# ATtiny1626 register map
Vendor: Atmel; File version: 1.0
CPU: other r0p0, little endian, no MPU, no FPU, 4 interrupt priority bits
Registers are 8-bit, read-write, reset 0x0 unless marked. A register's access mark holds for its fields unless they carry their own. Offsets are from the block's base; [hi:lo] are bit positions; {n}, {i} and the like mark numbered series.

## CLKCTRL — Clock controller
Base 0x00800060
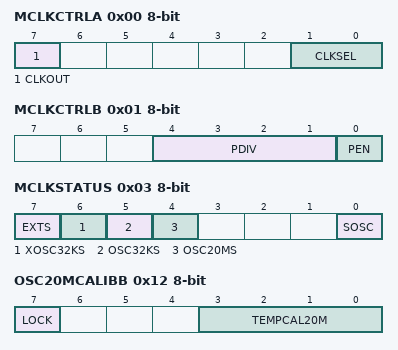
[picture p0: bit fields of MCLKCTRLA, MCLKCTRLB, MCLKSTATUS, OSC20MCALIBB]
0x00 MCLKCTRLA — MCLK Control A
  [7] CLKOUT — System clock out
  [1:0] CLKSEL — Clock
    0=OSC20M (20MHz oscillator); 1=OSCULP32K (32KHz oscillator); 2=XOSC32K (32.768kHz crystal oscillator); 3=EXTCLK (External clock)
0x01 MCLKCTRLB — MCLK Control B
  [4:1] PDIV — Prescaler division
    0=2X; 1=4X; 2=8X; 3=16X; 4=32X; 5=64X; 8=6X; 9=10X; 10=12X; 11=24X; 12=48X
  [0] PEN — Prescaler enable
0x02 MCLKLOCK
  [0] LOCKEN — lock ebable
0x03 MCLKSTATUS ro
  [7] EXTS — External Clock status
  [6] XOSC32KS — 32.768 kHz Crystal Oscillator status
  [5] OSC32KS — 32KHz oscillator status
  [4] OSC20MS — 20MHz oscillator status
  [0] SOSC — System Oscillator changing
0x10 OSC20MCTRLA — OSC20M Control A
  [1] RUNSTDBY — Run standby
0x11 OSC20MCALIBA — OSC20M Calibration A
  [6:0] CAL20M — Calibration
0x12 OSC20MCALIBB — OSC20M Calibration B
  [7] LOCK
  [3:0] TEMPCAL20M — Oscillator temperature coefficient
0x18 OSC32KCTRLA — OSC32K Control A
  [1] RUNSTDBY — Run standby
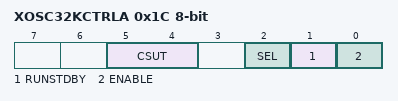
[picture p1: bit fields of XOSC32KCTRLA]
0x1C XOSC32KCTRLA — XOSC32K Control A
  [5:4] CSUT — Crystal startup time
    0=1K (1k cycles); 1=16K (16k cycles); 2=32K (32k cycles); 3=64K (64k cycles)
  [2] SEL — Select
  [1] RUNSTDBY — Run standby
  [0] ENABLE

## CPU
Base 0x00800034
0x00 CCP — Configuration Change Protection
  [7:0] CCP — CCP signature
    157=SPM (SPM Instruction Protection); 216=IOREG (IO Register Protection)
0x09 SP 16-bit (reset mask 0xFF) — Stack Pointer
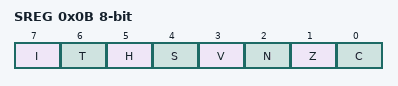
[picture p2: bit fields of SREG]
0x0B SREG — Status Register
  [7] I — Global Interrupt Enable Flag
  [6] T — Transfer Bit
  [5] H — Half Carry Flag
  [4] S — N Exclusive Or V Flag
  [3] V — Two's Complement Overflow Flag
  [2] N — Negative Flag
  [1] Z — Zero Flag
  [0] C — Carry Flag

## CPUINT — Interrupt Controller
Base 0x00800110
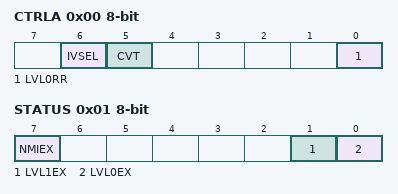
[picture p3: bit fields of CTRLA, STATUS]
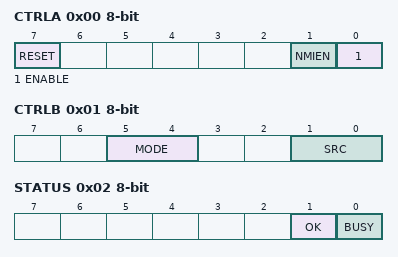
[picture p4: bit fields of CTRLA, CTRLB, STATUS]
0x00 CTRLA — Control A
  [6] IVSEL — Interrupt Vector Select
  [5] CVT — Compact Vector Table
  [0] LVL0RR — Round-robin Scheduling Enable
0x01 STATUS
  [7] NMIEX ro — Non-maskable Interrupt Executing
  [1] LVL1EX ro — Level 1 Interrupt Executing
  [0] LVL0EX ro — Level 0 Interrupt Executing
0x02 LVL0PRI — Interrupt Level 0 Priority
  [7:0] LVL0PRI — Interrupt Level Priority
0x03 LVL1VEC — Interrupt Level 1 Priority Vector
  [7:0] LVL1VEC — Interrupt Vector with High Priority

## CRCSCAN
Base 0x00800120
0x00 CTRLA — Control A
  [7] RESET — Reset CRC scan
  [1] NMIEN — Enable NMI Trigger
  [0] ENABLE — Enable CRC scan
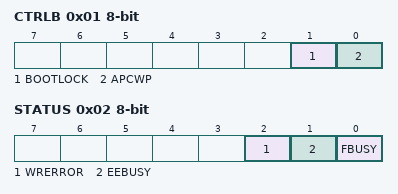
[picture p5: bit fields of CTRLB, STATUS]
0x01 CTRLB — Control B
  [5:4] MODE — CRC Flash Access Mode
    0=PRIORITY (Priority to flash)
  [1:0] SRC — CRC Source
    0=FLASH (CRC on entire flash); 1=APPLICATION (CRC on boot and appl section of flash); 2=BOOT (CRC on boot section of flash)
0x02 STATUS ro
  [1] OK — CRC Ok
  [0] BUSY — CRC Busy

## GPIO — General Purpose I/O Register
Base 0x0080001C
{0x0+i} GPIOR{i} (i=0..3) — General Purpose IO Register {i}

## NVMCTRL — Non-volatile Memory Controller
Base 0x00801000
0x00 CTRLA — Control A
  [2:0] CMD — Command
    0=NONE (No Command); 1=PAGEWRITE (Write page); 2=PAGEERASE (Erase page); 3=PAGEERASEWRITE (Erase and write page); 4=PAGEBUFCLR (Page buffer clear); 5=CHIPERASE; 6=EEERASE (EEPROM erase); 7=FUSEWRITE (Write fuse (PDI only))
0x01 CTRLB — Control B
  [1] BOOTLOCK
  [0] APCWP — Application code write protect
0x02 STATUS ro
  [2] WRERROR — Write error
  [1] EEBUSY — EEPROM busy
  [0] FBUSY — Flash busy
0x03 INTCTRL — Interrupt Control
  [0] EEREADY — EEPROM Ready
0x04 INTFLAGS — Interrupt Flags
  [0] EEREADY — EEPROM Ready
0x06 DATA 16-bit (reset mask 0xFF)
0x08 ADDR 16-bit (reset mask 0xFF) — Address

## PORTA — I/O Ports
Base 0x00800400
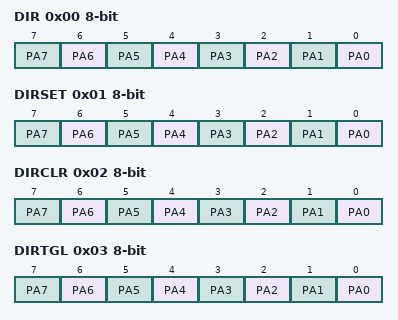
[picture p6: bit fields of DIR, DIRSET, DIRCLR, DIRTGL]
0x00 DIR — Data Direction
  [n] PA{n} (n=0..7) — Pin A{n}
0x01 DIRSET — Data Direction Set
  [n] PA{n} (n=0..7) — Pin A{n}
0x02 DIRCLR — Data Direction Clear
  [n] PA{n} (n=0..7) — Pin A{n}
0x03 DIRTGL — Data Direction Toggle
  [n] PA{n} (n=0..7) — Pin A{n}
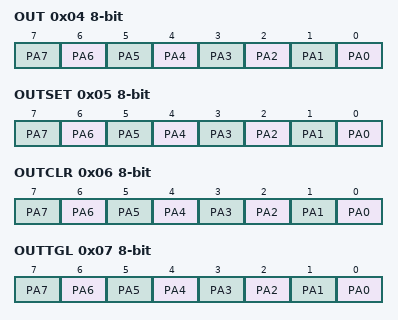
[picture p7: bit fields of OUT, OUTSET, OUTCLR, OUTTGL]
0x04 OUT — Output Value
  [n] PA{n} (n=0..7) — Pin A{n}
0x05 OUTSET — Output Value Set
  [n] PA{n} (n=0..7) — Pin A{n}
0x06 OUTCLR — Output Value Clear
  [n] PA{n} (n=0..7) — Pin A{n}
0x07 OUTTGL — Output Value Toggle
  [n] PA{n} (n=0..7) — Pin A{n}
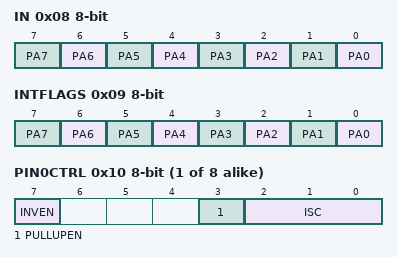
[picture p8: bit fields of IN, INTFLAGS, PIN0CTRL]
0x08 IN — Input Value
  [n] PA{n} (n=0..7) — Pin A{n}
0x09 INTFLAGS — Interrupt Flags
  [n] PA{n} (n=0..7) — Pin A{n}
0x0A PORTCTRL — Port Control
  [0] SRL — Slew Rate Limit Enable
{0x10+i} PIN{i}CTRL (i=0..7) — Pin {i} Control
  [7] INVEN — Inverted I/O Enable
  [3] PULLUPEN — Pullup enable
  [2:0] ISC — Input/Sense Configuration
    0=INTDISABLE (Interrupt disabled but input buffer enabled); 1=BOTHEDGES (Sense Both Edges); 2=RISING (Sense Rising Edge); 3=FALLING (Sense Falling Edge); 4=INPUT_DISABLE (Digital Input Buffer disabled); 5=LEVEL (Sense low Level)

## PORTB — I/O Ports
Base 0x00800420
Registers as PORTA; these are added or differ:
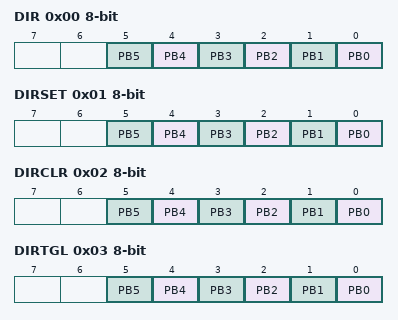
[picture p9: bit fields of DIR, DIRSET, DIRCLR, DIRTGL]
0x00 DIR — Data Direction
  [n] PB{n} (n=0..5) — Pin B{n}
0x01 DIRSET — Data Direction Set
  [n] PB{n} (n=0..5) — Pin B{n}
0x02 DIRCLR — Data Direction Clear
  [n] PB{n} (n=0..5) — Pin B{n}
0x03 DIRTGL — Data Direction Toggle
  [n] PB{n} (n=0..5) — Pin B{n}
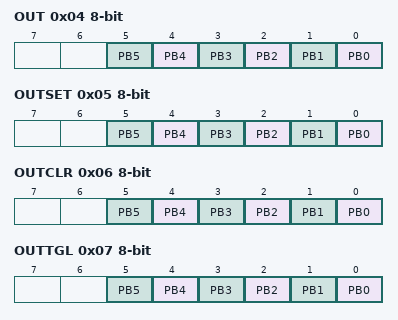
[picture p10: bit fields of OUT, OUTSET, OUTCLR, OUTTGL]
0x04 OUT — Output Value
  [n] PB{n} (n=0..5) — Pin B{n}
0x05 OUTSET — Output Value Set
  [n] PB{n} (n=0..5) — Pin B{n}
0x06 OUTCLR — Output Value Clear
  [n] PB{n} (n=0..5) — Pin B{n}
0x07 OUTTGL — Output Value Toggle
  [n] PB{n} (n=0..5) — Pin B{n}
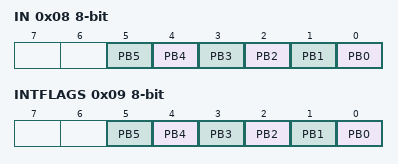
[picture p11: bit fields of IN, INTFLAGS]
0x08 IN — Input Value
  [n] PB{n} (n=0..5) — Pin B{n}
0x09 INTFLAGS — Interrupt Flags
  [n] PB{n} (n=0..5) — Pin B{n}

## PORTC — I/O Ports
Base 0x00800440
Registers as PORTA, without PORTCTRL; these are added or differ:
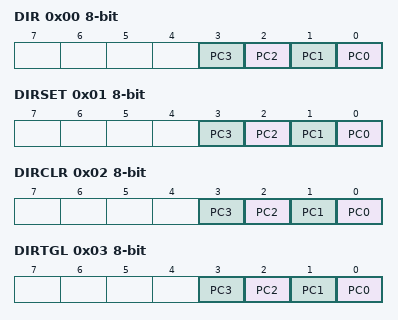
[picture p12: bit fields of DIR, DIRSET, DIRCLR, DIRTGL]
0x00 DIR — Data Direction
  [n] PC{n} (n=0..3) — Pin C{n}
0x01 DIRSET — Data Direction Set
  [n] PC{n} (n=0..3) — Pin C{n}
0x02 DIRCLR — Data Direction Clear
  [n] PC{n} (n=0..3) — Pin C{n}
0x03 DIRTGL — Data Direction Toggle
  [n] PC{n} (n=0..3) — Pin C{n}
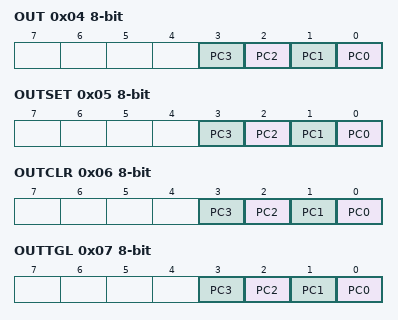
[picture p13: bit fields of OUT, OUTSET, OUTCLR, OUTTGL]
0x04 OUT — Output Value
  [n] PC{n} (n=0..3) — Pin C{n}
0x05 OUTSET — Output Value Set
  [n] PC{n} (n=0..3) — Pin C{n}
0x06 OUTCLR — Output Value Clear
  [n] PC{n} (n=0..3) — Pin C{n}
0x07 OUTTGL — Output Value Toggle
  [n] PC{n} (n=0..3) — Pin C{n}
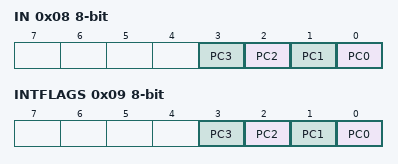
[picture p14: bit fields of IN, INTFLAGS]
0x08 IN — Input Value
  [n] PC{n} (n=0..3) — Pin C{n}
0x09 INTFLAGS — Interrupt Flags
  [n] PC{n} (n=0..3) — Pin C{n}
0x0A PORTCTRL — Port Control
  [0] SRL — Slew Rate Limit Enable
